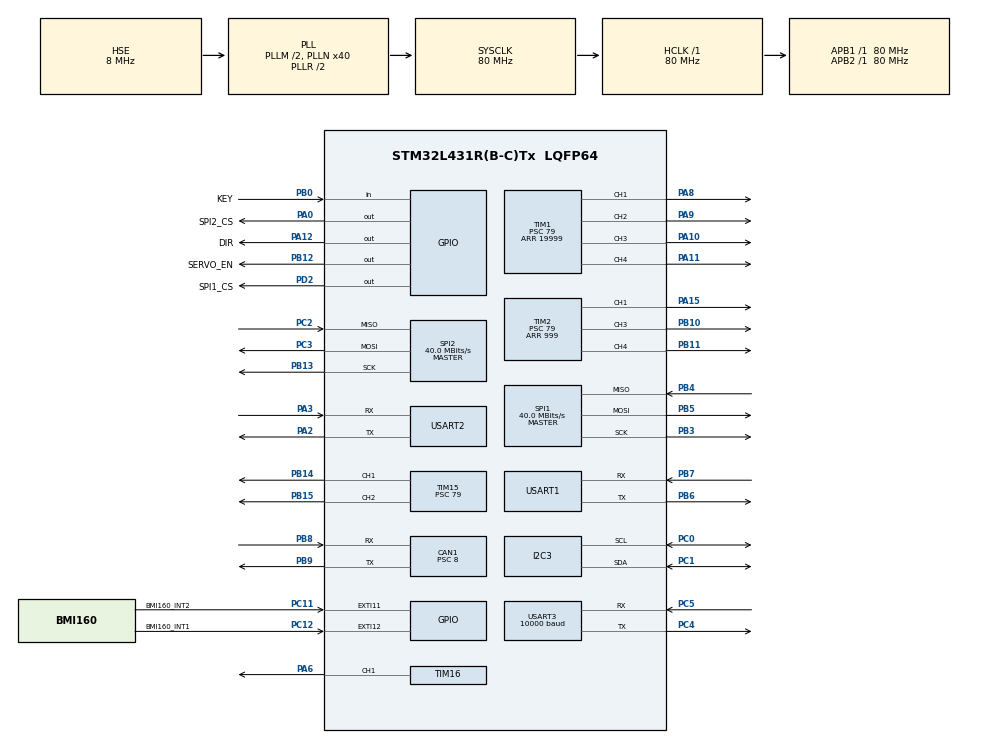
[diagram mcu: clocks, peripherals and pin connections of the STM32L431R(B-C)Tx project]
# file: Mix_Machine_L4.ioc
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CAN1.BS1=CAN_BS1_4TQ
CAN1.BS2=CAN_BS2_5TQ
CAN1.CalculateBaudRate=1000000
CAN1.CalculateTimeBit=1000
CAN1.CalculateTimeQuantum=100.0
CAN1.Prescaler=8
Dma.Request0=USART2_TX
Dma.Request1=USART2_RX
Dma.Request2=USART3_RX
Dma.Request3=USART1_RX
Dma.Request4=USART1_TX
Dma.USART1_RX.3.Direction=DMA_PERIPH_TO_MEMORY
Dma.USART1_RX.3.Instance=DMA1_Channel5
Dma.USART1_RX.3.MemDataAlignment=DMA_MDATAALIGN_BYTE
Dma.USART1_RX.3.MemInc=DMA_MINC_ENABLE
Dma.USART1_RX.3.Mode=DMA_NORMAL
Dma.USART1_RX.3.PeriphDataAlignment=DMA_PDATAALIGN_BYTE
Dma.USART1_RX.3.PeriphInc=DMA_PINC_DISABLE
Dma.USART1_RX.3.Priority=DMA_PRIORITY_LOW
Dma.USART1_TX.4.Direction=DMA_MEMORY_TO_PERIPH
Dma.USART1_TX.4.Instance=DMA1_Channel4
Dma.USART1_TX.4.MemDataAlignment=DMA_MDATAALIGN_BYTE
Dma.USART1_TX.4.MemInc=DMA_MINC_ENABLE
Dma.USART1_TX.4.Mode=DMA_NORMAL
Dma.USART1_TX.4.PeriphDataAlignment=DMA_PDATAALIGN_BYTE
Dma.USART1_TX.4.PeriphInc=DMA_PINC_DISABLE
Dma.USART1_TX.4.Priority=DMA_PRIORITY_LOW
Dma.USART2_RX.1.Direction=DMA_PERIPH_TO_MEMORY
Dma.USART2_RX.1.Instance=DMA1_Channel6
Dma.USART2_RX.1.MemDataAlignment=DMA_MDATAALIGN_BYTE
Dma.USART2_RX.1.MemInc=DMA_MINC_ENABLE
Dma.USART2_RX.1.Mode=DMA_NORMAL
Dma.USART2_RX.1.PeriphDataAlignment=DMA_PDATAALIGN_BYTE
Dma.USART2_RX.1.PeriphInc=DMA_PINC_DISABLE
Dma.USART2_RX.1.Priority=DMA_PRIORITY_HIGH
Dma.USART2_TX.0.Direction=DMA_MEMORY_TO_PERIPH
Dma.USART2_TX.0.Instance=DMA1_Channel7
Dma.USART2_TX.0.MemDataAlignment=DMA_MDATAALIGN_BYTE
Dma.USART2_TX.0.MemInc=DMA_MINC_ENABLE
Dma.USART2_TX.0.Mode=DMA_NORMAL
Dma.USART2_TX.0.PeriphDataAlignment=DMA_PDATAALIGN_BYTE
Dma.USART2_TX.0.PeriphInc=DMA_PINC_DISABLE
Dma.USART2_TX.0.Priority=DMA_PRIORITY_HIGH
Dma.USART3_RX.2.Direction=DMA_PERIPH_TO_MEMORY
Dma.USART3_RX.2.Instance=DMA1_Channel3
Dma.USART3_RX.2.MemDataAlignment=DMA_MDATAALIGN_BYTE
Dma.USART3_RX.2.MemInc=DMA_MINC_ENABLE
Dma.USART3_RX.2.Mode=DMA_NORMAL
Dma.USART3_RX.2.PeriphDataAlignment=DMA_PDATAALIGN_BYTE
Dma.USART3_RX.2.PeriphInc=DMA_PINC_DISABLE
Dma.USART3_RX.2.Priority=DMA_PRIORITY_HIGH
FREERTOS.Tasks01=defaultTask,0,128,StartDefaultTask,Default,NULL,Dynamic,NULL,NULL
FREERTOS.configTOTAL_HEAP_SIZE=20480
I2C3.Timing=0x10909CEC
Mcu.Family=STM32L4
Mcu.Name=STM32L431R(B-C)Tx
Mcu.Package=LQFP64
NVIC.CAN1_RX0_IRQn=true\:5\:0\:true\:false\:true\:true\:true\:true\:true
NVIC.CAN1_RX1_IRQn=true\:5\:0\:false\:false\:true\:true\:true\:true\:true
NVIC.DMA1_Channel3_IRQn=true\:5\:0\:false\:false\:true\:true\:false\:true\:true
NVIC.DMA1_Channel4_IRQn=true\:5\:0\:false\:false\:true\:true\:false\:true\:true
NVIC.DMA1_Channel5_IRQn=true\:5\:0\:false\:false\:true\:true\:false\:true\:true
NVIC.DMA1_Channel6_IRQn=true\:5\:0\:false\:false\:true\:true\:false\:true\:true
NVIC.DMA1_Channel7_IRQn=true\:5\:0\:false\:false\:true\:true\:false\:true\:true
NVIC.PriorityGroup=NVIC_PRIORITYGROUP_4
NVIC.TIM6_DAC_IRQn=true\:5\:0\:false\:false\:true\:true\:true\:true\:true
NVIC.TIM7_IRQn=true\:15\:0\:false\:false\:true\:false\:false\:true\:true
NVIC.TimeBase=TIM7_IRQn
NVIC.TimeBaseIP=TIM7
NVIC.USART3_IRQn=true\:5\:0\:false\:false\:true\:true\:true\:true\:true
PA0.GPIO_Label=SPI2_CS
PA0.Signal=GPIO_Output
PA10.Signal=S_TIM1_CH3
PA11.Signal=S_TIM1_CH4
PA12.GPIO_Label=DIR
PA12.GPIO_PuPd=GPIO_PULLUP
PA12.PinState=GPIO_PIN_SET
PA12.Signal=GPIO_Output
PA13\ (JTMS-SWDIO).Mode=Serial_Wire
PA13\ (JTMS-SWDIO).Signal=SYS_JTMS-SWDIO
PA14\ (JTCK-SWCLK).Mode=Serial_Wire
PA14\ (JTCK-SWCLK).Signal=SYS_JTCK-SWCLK
PA15\ (JTDI).GPIO_PuPd=GPIO_PULLDOWN
PA15\ (JTDI).Signal=S_TIM2_CH1
PA2.Mode=Asynchronous
PA2.Signal=USART2_TX
PA3.Mode=Asynchronous
PA3.Signal=USART2_RX
PA6.GPIO_PuPd=GPIO_PULLUP
PA6.Signal=S_TIM16_CH1
PA8.Signal=S_TIM1_CH1
PA9.Signal=S_TIM1_CH2
PB0.GPIO_Label=KEY
PB0.GPIO_PuPd=GPIO_PULLUP
PB0.Signal=GPIO_Input
PB10.GPIO_PuPd=GPIO_PULLUP
PB10.Signal=S_TIM2_CH3
PB11.GPIO_PuPd=GPIO_PULLUP
PB11.Signal=S_TIM2_CH4
PB12.GPIO_Label=SERVO_EN
PB12.GPIO_PuPd=GPIO_PULLDOWN
PB12.Signal=GPIO_Output
PB13.Mode=Full_Duplex_Master
PB13.Signal=SPI2_SCK
PB14.Signal=S_TIM15_CH1
PB15.Signal=S_TIM15_CH2
PB3\ (JTDO-TRACESWO).Mode=Full_Duplex_Master
PB3\ (JTDO-TRACESWO).Signal=SPI1_SCK
PB4\ (NJTRST).Mode=Full_Duplex_Master
PB4\ (NJTRST).Signal=SPI1_MISO
PB5.Mode=Full_Duplex_Master
PB5.Signal=SPI1_MOSI
PB6.Mode=Asynchronous
PB6.Signal=USART1_TX
PB7.Mode=Asynchronous
PB7.Signal=USART1_RX
PB8.Mode=CAN_Activate
PB8.Signal=CAN1_RX
PB9.Mode=CAN_Activate
PB9.Signal=CAN1_TX
PC0.Mode=I2C
PC0.Signal=I2C3_SCL
PC1.Mode=I2C
PC1.Signal=I2C3_SDA
PC11.GPIO_Label=BMI160_INT2
PC11.Signal=GPXTI11
PC12.GPIO_Label=BMI160_INT1
PC12.Signal=GPXTI12
PC2.Mode=Full_Duplex_Master
PC2.Signal=SPI2_MISO
PC3.Mode=Full_Duplex_Master
PC3.Signal=SPI2_MOSI
PC4.Mode=Asynchronous
PC4.Signal=USART3_TX
PC5.Mode=Asynchronous
PC5.Signal=USART3_RX
PD2.GPIO_Label=SPI1_CS
PD2.GPIO_Speed=GPIO_SPEED_FREQ_HIGH
PD2.PinState=GPIO_PIN_SET
PD2.Signal=GPIO_Output
PH0-OSC_IN\ (PH0).Mode=HSE-External-Oscillator
PH0-OSC_IN\ (PH0).Signal=RCC_OSC_IN
PH1-OSC_OUT\ (PH1).Mode=HSE-External-Oscillator
PH1-OSC_OUT\ (PH1).Signal=RCC_OSC_OUT
ProjectManager.HeapSize=0x200
ProjectManager.StackSize=0x400
ProjectManager.TargetToolchain=MDK-ARM V5.32
RCC.ADCFreq_Value=16000000
RCC.AHBFreq_Value=80000000
RCC.APB1Freq_Value=80000000
RCC.APB1TimFreq_Value=80000000
RCC.APB2Freq_Value=80000000
RCC.APB2TimFreq_Value=80000000
RCC.CortexFreq_Value=80000000
RCC.HCLKFreq_Value=80000000
RCC.HSE_VALUE=8000000
RCC.HSI48_VALUE=48000000
RCC.HSI_VALUE=16000000
RCC.LSE_VALUE=32768
RCC.MSI_VALUE=4000000
RCC.PLLM=2
RCC.PLLN=40
RCC.PLLSourceVirtual=RCC_PLLSOURCE_HSE
RCC.SYSCLKFreq_VALUE=80000000
RCC.SYSCLKSource=RCC_SYSCLKSOURCE_PLLCLK
RCC.VCOOutputFreq_Value=160000000
SH.S_TIM15_CH1.0=TIM15_CH1,PWM Generation1 CH1
SH.S_TIM15_CH2.0=TIM15_CH2,PWM Generation2 CH2
SH.S_TIM16_CH1.0=TIM16_CH1,PWM Generation1 CH1
SH.S_TIM1_CH1.0=TIM1_CH1,PWM Generation1 CH1
SH.S_TIM1_CH2.0=TIM1_CH2,PWM Generation2 CH2
SH.S_TIM1_CH3.0=TIM1_CH3,PWM Generation3 CH3
SH.S_TIM1_CH4.0=TIM1_CH4,PWM Generation4 CH4
SH.S_TIM2_CH1.0=TIM2_CH1,PWM Generation1 CH1
SH.S_TIM2_CH3.0=TIM2_CH3,PWM Generation3 CH3
SH.S_TIM2_CH4.0=TIM2_CH4,PWM Generation4 CH4
SPI1.CalculateBaudRate=40.0 MBits/s
SPI1.Direction=SPI_DIRECTION_2LINES
SPI1.Mode=SPI_MODE_MASTER
SPI1.VirtualType=VM_MASTER
SPI2.CalculateBaudRate=40.0 MBits/s
SPI2.Direction=SPI_DIRECTION_2LINES
SPI2.Mode=SPI_MODE_MASTER
SPI2.VirtualType=VM_MASTER
TIM1.Channel-PWM\ Generation1\ CH1=TIM_CHANNEL_1
TIM1.Channel-PWM\ Generation2\ CH2=TIM_CHANNEL_2
TIM1.Channel-PWM\ Generation3\ CH3=TIM_CHANNEL_3
TIM1.Channel-PWM\ Generation4\ CH4=TIM_CHANNEL_4
TIM1.Period=19999
TIM1.Prescaler=79
TIM1.Pulse-PWM\ Generation1\ CH1=1499
TIM1.Pulse-PWM\ Generation2\ CH2=1499
TIM1.Pulse-PWM\ Generation3\ CH3=1499
TIM1.Pulse-PWM\ Generation4\ CH4=1499
TIM15.Channel-PWM\ Generation1\ CH1=TIM_CHANNEL_1
TIM15.Channel-PWM\ Generation2\ CH2=TIM_CHANNEL_2
TIM15.Period=19999
TIM15.Prescaler=79
TIM15.Pulse-PWM\ Generation1\ CH1=1499
TIM15.Pulse-PWM\ Generation2\ CH2=1499
TIM16.Channel=TIM_CHANNEL_1
TIM16.Period=999
TIM16.Prescaler=79
TIM16.Pulse=999
TIM2.Channel-PWM\ Generation1\ CH1=TIM_CHANNEL_1
TIM2.Channel-PWM\ Generation3\ CH3=TIM_CHANNEL_3
TIM2.Channel-PWM\ Generation4\ CH4=TIM_CHANNEL_4
TIM2.Period=999
TIM2.Prescaler=79
TIM2.Pulse-PWM\ Generation3\ CH3=999
TIM2.Pulse-PWM\ Generation4\ CH4=999
TIM6.Period=999
TIM6.Prescaler=79
USART1.VirtualMode-Asynchronous=VM_ASYNC
USART2.VirtualMode-Asynchronous=VM_ASYNC
USART3.BaudRate=10000
USART3.Parity=PARITY_EVEN
USART3.VirtualMode-Asynchronous=VM_ASYNC
USART3.WordLength=WORDLENGTH_9B
VP_FREERTOS_VS_CMSIS_V1.Mode=CMSIS_V1
VP_SYS_VS_tim7.Mode=TIM7
VP_TIM15_VS_ClockSourceINT.Mode=Internal
VP_TIM16_VS_ClockSourceINT.Mode=Enable_Timer
VP_TIM1_VS_ClockSourceINT.Mode=Internal
VP_TIM2_VS_ClockSourceINT.Mode=Internal
VP_TIM6_VS_ClockSourceINT.Mode=Enable_Timer
board=custom

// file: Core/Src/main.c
/* USER CODE BEGIN Header */
/**
  ******************************************************************************
  * @file           : main.c
  * @brief          : Main program body
  ******************************************************************************
  * @attention
  *
  * Copyright (c) 2022 STMicroelectronics.
  * All rights reserved.
  *
  * This software is licensed under terms that can be found in the LICENSE file
  * in the root directory of this software component.
  * If no LICENSE file comes with this software, it is provided AS-IS.
  *
  ******************************************************************************
  */
/* USER CODE END Header */
#include "main.h"
#include "cmsis_os.h"
#include "can.h"
#include "dma.h"
#include "i2c.h"
#include "spi.h"
#include "tim.h"
#include "usart.h"
#include "gpio.h"

/* USER CODE BEGIN PM */
uint8_t Power = 0;
/* USER CODE END PM */

void SystemClock_Config(void);
void MX_FREERTOS_Init(void);

int main(void)
{

  /* MCU Configuration--------------------------------------------------------*/

  /* Reset of all peripherals, Initializes the Flash interface and the Systick. */
  HAL_Init();

  /* Configure the system clock */
  SystemClock_Config();

  /* Initialize all configured peripherals */
  MX_GPIO_Init();
  MX_DMA_Init();
  MX_CAN1_Init();
  MX_TIM1_Init();
  MX_TIM2_Init();
  MX_TIM6_Init();
  MX_TIM15_Init();
  MX_TIM16_Init();
  MX_USART2_UART_Init();
  MX_USART3_UART_Init();
  MX_I2C3_Init();
  MX_SPI1_Init();
  MX_SPI2_Init();
  MX_USART1_UART_Init();
  /* USER CODE BEGIN 2 */
  HAL_TIM_PWM_Start(&htim2,TIM_CHANNEL_3);
  HAL_TIM_PWM_Start(&htim2,TIM_CHANNEL_4);
  HAL_TIM_PWM_Start(&htim16,TIM_CHANNEL_1);
  HAL_TIM_PWM_Start(&htim1,TIM_CHANNEL_1);
  HAL_TIM_PWM_Start(&htim1,TIM_CHANNEL_2);
  HAL_TIM_PWM_Start(&htim1,TIM_CHANNEL_3);
  HAL_TIM_PWM_Start(&htim1,TIM_CHANNEL_4);
  HAL_TIM_PWM_Start(&htim15,TIM_CHANNEL_1);
  HAL_TIM_PWM_Start(&htim15,TIM_CHANNEL_2);
  /* USER CODE END 2 */

  /* Call init function for freertos objects (in freertos.c) */
  MX_FREERTOS_Init();

  /* Start scheduler */
  osKernelStart();

  /* We should never get here as control is now taken by the scheduler */
  /* Infinite loop */
  while (1)
  {

  }
}

void SystemClock_Config(void)
{
  RCC_OscInitTypeDef RCC_OscInitStruct = {0};
  RCC_ClkInitTypeDef RCC_ClkInitStruct = {0};

  /** Configure the main internal regulator output voltage
  */
  if (HAL_PWREx_ControlVoltageScaling(PWR_REGULATOR_VOLTAGE_SCALE1) != HAL_OK)
  {
    Error_Handler();
  }

  /** Initializes the RCC Oscillators according to the specified parameters
  * in the RCC_OscInitTypeDef structure.
  */
  RCC_OscInitStruct.OscillatorType = RCC_OSCILLATORTYPE_HSE;
  RCC_OscInitStruct.HSEState = RCC_HSE_ON;
  RCC_OscInitStruct.PLL.PLLState = RCC_PLL_ON;
  RCC_OscInitStruct.PLL.PLLSource = RCC_PLLSOURCE_HSE;
  RCC_OscInitStruct.PLL.PLLM = 2;
  RCC_OscInitStruct.PLL.PLLN = 40;
  RCC_OscInitStruct.PLL.PLLP = RCC_PLLP_DIV7;
  RCC_OscInitStruct.PLL.PLLQ = RCC_PLLQ_DIV2;
  RCC_OscInitStruct.PLL.PLLR = RCC_PLLR_DIV2;
  if (HAL_RCC_OscConfig(&RCC_OscInitStruct) != HAL_OK)
  {
    Error_Handler();
  }

  /** Initializes the CPU, AHB and APB buses clocks
  */
  RCC_ClkInitStruct.ClockType = RCC_CLOCKTYPE_HCLK|RCC_CLOCKTYPE_SYSCLK
                              |RCC_CLOCKTYPE_PCLK1|RCC_CLOCKTYPE_PCLK2;
  RCC_ClkInitStruct.SYSCLKSource = RCC_SYSCLKSOURCE_PLLCLK;
  RCC_ClkInitStruct.AHBCLKDivider = RCC_SYSCLK_DIV1;
  RCC_ClkInitStruct.APB1CLKDivider = RCC_HCLK_DIV1;
  RCC_ClkInitStruct.APB2CLKDivider = RCC_HCLK_DIV1;

  if (HAL_RCC_ClockConfig(&RCC_ClkInitStruct, FLASH_LATENCY_4) != HAL_OK)
  {
    Error_Handler();
  }
}

void HAL_TIM_PeriodElapsedCallback(TIM_HandleTypeDef *htim)
{
  if (htim->Instance == TIM7) {
    HAL_IncTick();
  }
}

void Error_Handler(void)
{
  __disable_irq();
  while (1)
  {
  }
}
